# GD32F5xx register map
File version: 1.0
CPU: CM33 r0p1, little endian, MPU, FPU, 4 interrupt priority bits
Registers are 32-bit, read-write, reset 0x0 unless marked. A register's access mark holds for its fields unless they carry their own. Offsets are from the block's base; [hi:lo] are bit positions; {n}, {i} and the like mark numbered series.

## RCU — Reset and clock unit
Base 0x40023800
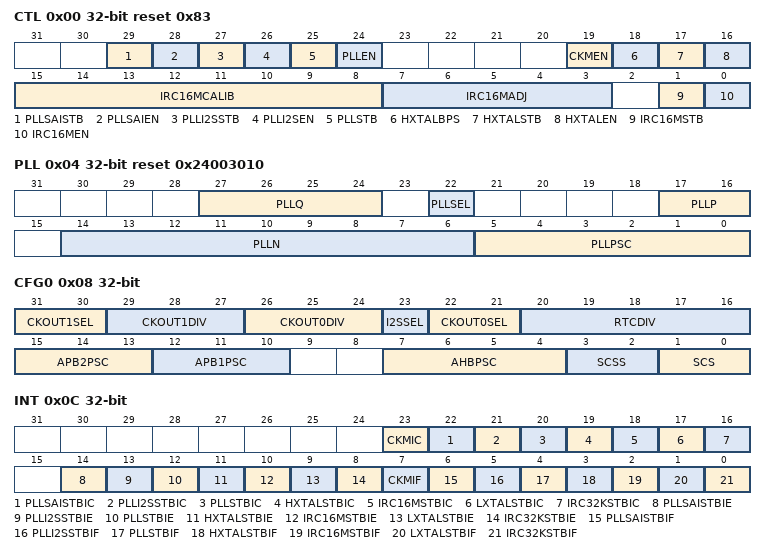
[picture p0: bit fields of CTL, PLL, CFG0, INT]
0x00 CTL access per field reset 0x83 — Control register
  [29] PLLSAISTB ro — PLLSAI clock stabilization flag
  [28] PLLSAIEN rw — PLLSAI enable
  [27] PLLI2SSTB ro — PLLI2S clock stabilization flag
  [26] PLLI2SEN rw — PLLI2S enable
  [25] PLLSTB ro — PLL clock stabilization flag
  [24] PLLEN rw — PLL enable
  [19] CKMEN rw — HXTAL clock monitor enable
  [18] HXTALBPS rw — High speed crystal oscillator (HXTAL) clock bypass mode enable
  [17] HXTALSTB ro — High speed crystal oscillator (HXTAL) clock stabilization flag
  [16] HXTALEN rw — High Speed crystal oscillator (HXTAL) enable
  [15:8] IRC16MCALIB ro — Internal 16MHz RC Oscillator calibration value register
  [7:3] IRC16MADJ rw — Internal 16MHz RC Oscillator clock trim adjust value
  [1] IRC16MSTB ro — IRC16M Internal 16MHz RC Oscillator stabilization flag
  [0] IRC16MEN rw — Internal 16MHz RC oscillator enable
0x04 PLL reset 0x24003010
  [27:24] PLLQ — The PLL Q output frequency division factor from PLL VCO clock
  [22] PLLSEL — PLL clock source selection
  [17:16] PLLP — The PLLP output frequency division factor from PLL VCO clock
  [14:6] PLLN — The PLL VCO clock multiplication factor
  [5:0] PLLPSC — The PLL VCO source clock prescaler
0x08 CFG0 access per field — Clock configuration register 0
  [31:30] CKOUT1SEL rw — CKOUT1 clock source selection
  [29:27] CKOUT1DIV rw — The CK_OUT1 divider which the CK_OUT1 frequency can be reduced
  [26:24] CKOUT0DIV rw — The CK_OUT0 divider which the CK_OUT0 frequency can be reduced
  [23] I2SSEL rw — I2S clock source selection
  [22:21] CKOUT0SEL rw — CKOUT0 clock source selection
  [20:16] RTCDIV rw — RTC clock divider factor
  [15:13] APB2PSC rw — APB2 prescaler selection
  [12:10] APB1PSC rw — APB1 prescaler selection
  [7:4] AHBPSC rw — AHB prescaler selection
  [3:2] SCSS ro — System clock switch status
  [1:0] SCS rw — System clock switch
0x0C INT access per field — Clock interrupt register
  [23] CKMIC wo — HXTAL clock stuck interrupt clear
  [22] PLLSAISTBIC wo — PLLSAI stabilization interrupt clear
  [21] PLLI2SSTBIC wo — PLLI2S stabilization interrupt clear
  [20] PLLSTBIC wo — PLL stabilization interrupt clear
  [19] HXTALSTBIC wo — HXTAL stabilization interrupt clear
  [18] IRC16MSTBIC wo — IRC16M stabilization interrupt clear
  [17] LXTALSTBIC wo — LXTAL stabilization interrupt clear
  [16] IRC32KSTBIC wo — IRC32K stabilization interrupt clear
  [14] PLLSAISTBIE rw — PLLSAI stabilization interrupt enable
  [13] PLLI2SSTBIE rw — PLLI2S stabilization interrupt enable
  [12] PLLSTBIE rw — PLL stabilization interrupt enable
  [11] HXTALSTBIE rw — HXTAL stabilization interrupt enable
  [10] IRC16MSTBIE rw — IRC16M stabilization interrupt enable
  [9] LXTALSTBIE rw — LXTAL stabilization interrupt enable
  [8] IRC32KSTBIE rw — IRC32K stabilization interrupt enable
  [7] CKMIF ro — HXTAL clock stuck interrupt flag
  [6] PLLSAISTBIF ro — PLLSAI stabilization interrupt flag
  [5] PLLI2SSTBIF ro — PLLI2S stabilization interrupt flag
  [4] PLLSTBIF ro — PLL stabilization interrupt flag
  [3] HXTALSTBIF ro — HXTAL stabilization interrupt flag
  [2] IRC16MSTBIF ro — IRC16M stabilization interrupt flag
  [1] LXTALSTBIF ro — LXTAL stabilization interrupt flag
  [0] IRC32KSTBIF ro — IRC32K stabilization interrupt flag
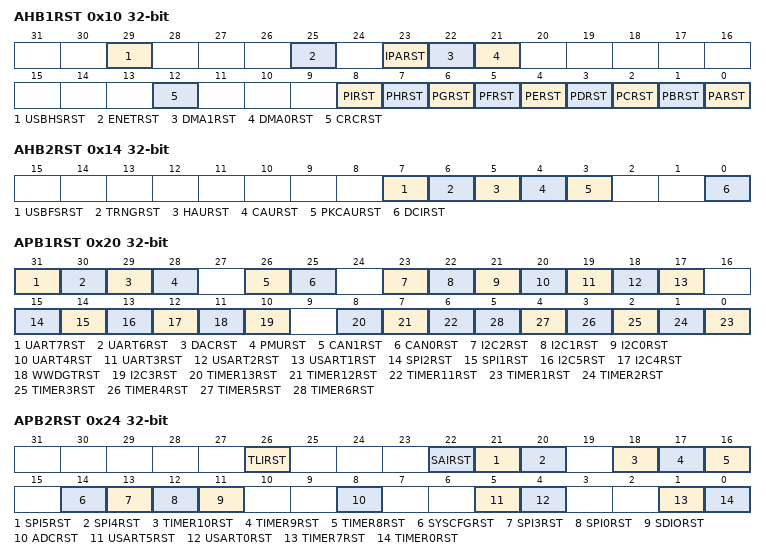
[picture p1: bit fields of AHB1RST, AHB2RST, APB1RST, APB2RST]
0x10 AHB1RST — AHB1 reset register
  [29] USBHSRST — USBHS reset
  [25] ENETRST — Ethernet reset
  [23] IPARST — IPA reset
  [22] DMA1RST — DMA1 reset
  [21] DMA0RST — DMA0 reset
  [12] CRCRST — CRC reset
  [8] PIRST — GPIO port I reset
  [7] PHRST — GPIO port H reset
  [6] PGRST — GPIO port G reset
  [5] PFRST — GPIO port F reset
  [4] PERST — GPIO port E reset
  [3] PDRST — GPIO port D reset
  [2] PCRST — GPIO port C reset
  [1] PBRST — GPIO port B reset
  [0] PARST — GPIO port A reset
0x14 AHB2RST — AHB2 reset register
  [7] USBFSRST — USBFS reset
  [6] TRNGRST — TRNG reset
  [5] HAURST — HAU reset
  [4] CAURST — CAU reset
  [3] PKCAURST — PKCAU reset
  [0] DCIRST — DCI reset
0x18 AHB3RST — AHB3 reset register
  [0] EXMCRST — EXMC reset
0x20 APB1RST — APB1 reset register
  [31] UART7RST — UART7 reset
  [30] UART6RST — UART6 reset
  [29] DACRST — DAC reset
  [28] PMURST — PMU reset
  [26] CAN1RST — CAN1 reset
  [25] CAN0RST — CAN0 reset
  [23] I2C2RST — I2C2 reset
  [22] I2C1RST — I2C1 reset
  [21] I2C0RST — I2C0 reset
  [20] UART4RST — UART4 reset
  [19] UART3RST — UART3 reset
  [18] USART2RST — USART2 reset
  [17] USART1RST — USART1 reset
  [15] SPI2RST — SPI2 reset
  [14] SPI1RST — SPI1 reset
  [13] I2C5RST — I2C5 reset
  [12] I2C4RST — I2C4 reset
  [11] WWDGTRST — WWDGT reset
  [10] I2C3RST — I2C3 reset
  [8] TIMER13RST — TIMER13 reset
  [7] TIMER12RST — TIMER12 reset
  [6] TIMER11RST — TIMER11 reset
  [n-1] TIMER{n}RST (n=1..6) — TIMER{n} reset
0x24 APB2RST — APB2 reset register
  [26] TLIRST — TLI reset
  [22] SAIRST — SAI reset
  [21] SPI5RST — SPI5 reset
  [20] SPI4RST — SPI4 reset
  [18] TIMER10RST — TIMER10 reset
  [17] TIMER9RST — TIMER9 reset
  [16] TIMER8RST — TIMER8 reset
  [14] SYSCFGRST — SYSCFG reset
  [13] SPI3RST — SPI3 reset
  [12] SPI0RST — SPI0 reset
  [11] SDIORST — SDIO reset
  [8] ADCRST — ADC reset
  [5] USART5RST — USART5 reset
  [4] USART0RST — USART0 reset
  [1] TIMER7RST — TIMER7 reset
  [0] TIMER0RST — TIMER0 reset
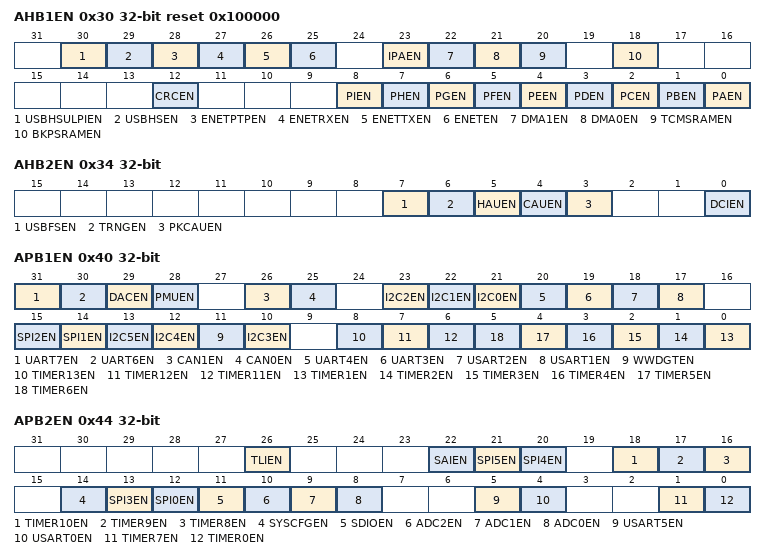
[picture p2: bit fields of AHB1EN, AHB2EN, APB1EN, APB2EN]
0x30 AHB1EN reset 0x100000 — AHB1 enable register
  [30] USBHSULPIEN — USBHS ULPI clock enable
  [29] USBHSEN — USBHS clock enable
  [28] ENETPTPEN — Ethernet PTP clock enable
  [27] ENETRXEN — Ethernet RX clock enable
  [26] ENETTXEN — Ethernet TX clock enable
  [25] ENETEN — Ethernet clock enable
  [23] IPAEN — IPA clock enable
  [22] DMA1EN — DMA1 clock enable
  [21] DMA0EN — DMA0 clock enable
  [20] TCMSRAMEN — TCMSRAM clock enable
  [18] BKPSRAMEN — BKPSRAM clock enable
  [12] CRCEN — CRC clock enable
  [8] PIEN — GPIO port I clock enable
  [7] PHEN — GPIO port H clock enable
  [6] PGEN — GPIO port G clock enable
  [5] PFEN — GPIO port F clock enable
  [4] PEEN — GPIO port E clock enable
  [3] PDEN — GPIO port D clock enable
  [2] PCEN — GPIO port C clock enable
  [1] PBEN — GPIO port B clock enable
  [0] PAEN — GPIO port A clock enable
0x34 AHB2EN — AHB2 enable register
  [7] USBFSEN — USBFS clock enable
  [6] TRNGEN — TRNG clock enable
  [5] HAUEN — HAU clock enable
  [4] CAUEN — CAU clock enable
  [3] PKCAUEN — PKCAU clock enable
  [0] DCIEN — DCI clock enable
0x38 AHB3EN — AHB3 enable register
  [0] EXMCEN — EXMC clock enable
0x40 APB1EN — APB1 enable register
  [31] UART7EN — UART7 clock enable
  [30] UART6EN — UART6 clock enable
  [29] DACEN — DAC clock enable
  [28] PMUEN — PMU clock enable
  [26] CAN1EN — CAN1 clock enable
  [25] CAN0EN — CAN0 clock enable
  [23] I2C2EN — I2C2 clock enable
  [22] I2C1EN — I2C1 clock enable
  [21] I2C0EN — I2C0 clock enable
  [20] UART4EN — UART4 clock enable
  [19] UART3EN — UART3 clock enable
  [18] USART2EN — USART2 clock enable
  [17] USART1EN — USART1 clock enable
  [15] SPI2EN — SPI2 clock enable
  [14] SPI1EN — SPI1 clock enable
  [13] I2C5EN — I2C5 clock enable
  [12] I2C4EN — I2C4 clock enable
  [11] WWDGTEN — WWDGT clock enable
  [10] I2C3EN — I2C3 clock enable
  [8] TIMER13EN — TIMER13 clock enable
  [7] TIMER12EN — TIMER12 clock enable
  [6] TIMER11EN — TIMER11 clock enable
  [n-1] TIMER{n}EN (n=1..6) — TIMER{n} clock enable
0x44 APB2EN — APB2 enable register
  [26] TLIEN — TLI clock enable
  [22] SAIEN — SAI clock enable
  [21] SPI5EN — SPI5 clock enable
  [20] SPI4EN — SPI4 clock enable
  [18] TIMER10EN — TIMER10 clock enable
  [17] TIMER9EN — TIMER9 clock enable
  [16] TIMER8EN — TIMER8 clock enable
  [14] SYSCFGEN — SYSCFG clock enable
  [13] SPI3EN — SPI3 clock enable
  [12] SPI0EN — SPI0 clock enable
  [11] SDIOEN — SDIO clock enable
  [10] ADC2EN — ADC2 clock enable
  [9] ADC1EN — ADC1 clock enable
  [8] ADC0EN — ADC0 clock enable
  [5] USART5EN — USART5 clock enable
  [4] USART0EN — USART0 clock enable
  [1] TIMER7EN — TIMER7 clock enable
  [0] TIMER0EN — TIMER0 clock enable
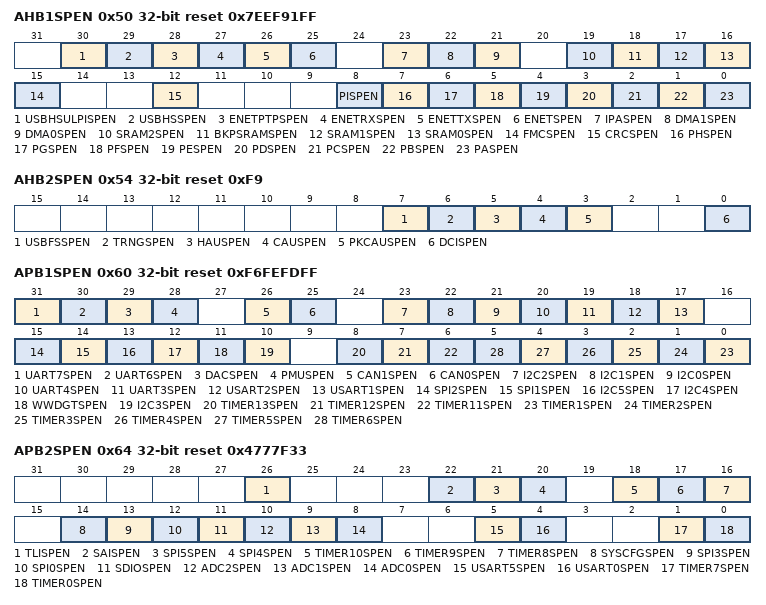
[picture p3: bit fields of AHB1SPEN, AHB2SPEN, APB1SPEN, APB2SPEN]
0x50 AHB1SPEN reset 0x7EEF91FF — AHB1 sleep mode enable register
  [30] USBHSULPISPEN — USBHS ULPI clock enable when sleep mode
  [29] USBHSSPEN — USBHS clock enable when sleep mode
  [28] ENETPTPSPEN — Ethernet PTP clock enable when sleep mode
  [27] ENETRXSPEN — Ethernet RX clock enable when sleep mode
  [26] ENETTXSPEN — Ethernet TX clock enable when sleep mode
  [25] ENETSPEN — Ethernet clock enable when sleep mode
  [23] IPASPEN — IPA clock enable when sleep mode
  [22] DMA1SPEN — DMA1 clock enable when sleep mode
  [21] DMA0SPEN — DMA0 clock enable when sleep mode
  [19] SRAM2SPEN — SRAM2 clock enable when sleep mode
  [18] BKPSRAMSPEN — BKPSRAM clock enable when sleep mode
  [17] SRAM1SPEN — SRAM1 clock enable when sleep mode
  [16] SRAM0SPEN — SRAM0 clock enable when sleep mode
  [15] FMCSPEN — FMC clock enable when sleep mode
  [12] CRCSPEN — CRC clock enable when sleep mode
  [8] PISPEN — GPIO port I clock enable when sleep mode
  [7] PHSPEN — GPIO port H clock enable when sleep mode
  [6] PGSPEN — GPIO port G clock enable when sleep mode
  [5] PFSPEN — GPIO port F clock enable when sleep mode
  [4] PESPEN — GPIO port E clock enable when sleep mode
  [3] PDSPEN — GPIO port D clock enable when sleep mode
  [2] PCSPEN — GPIO port C clock enable when sleep mode
  [1] PBSPEN — GPIO port B clock enable when sleep mode
  [0] PASPEN — GPIO port A clock enable when sleep mode
0x54 AHB2SPEN reset 0xF9 — AHB2 sleep mode enable register
  [7] USBFSSPEN — USBFS clock enable when sleep mode
  [6] TRNGSPEN — TRNG clock enable when sleep mode
  [5] HAUSPEN — HAU clock enable when sleep mode
  [4] CAUSPEN — CAU clock enable when sleep mode
  [3] PKCAUSPEN — PKCAU clock enable when sleep mode
  [0] DCISPEN — DCI clock enable when sleep mode
0x58 AHB3SPEN reset 0x1 — AHB3 sleep mode enable register
  [0] EXMCSPEN — EXMC clock enable when sleep mode
0x60 APB1SPEN reset 0xF6FEFDFF — APB1 sleep mode enable register
  [31] UART7SPEN — UART7 clock enable when sleep mode
  [30] UART6SPEN — UART6 clock enable when sleep mode
  [29] DACSPEN — DAC clock enable when sleep mode
  [28] PMUSPEN — PMU clock enable when sleep mode
  [26] CAN1SPEN — CAN1 clock enable when sleep mode
  [25] CAN0SPEN — CAN0 clock enable when sleep mode
  [23] I2C2SPEN — I2C2 clock enable when sleep mode
  [22] I2C1SPEN — I2C1 clock enable when sleep mode
  [21] I2C0SPEN — I2C0 clock enable when sleep mode
  [20] UART4SPEN — UART4 clock enable when sleep mode
  [19] UART3SPEN — UART3 clock enable when sleep mode
  [18] USART2SPEN — USART2 clock enable when sleep mode
  [17] USART1SPEN — USART1 clock enable when sleep mode
  [15] SPI2SPEN — SPI2 clock enable when sleep mode
  [14] SPI1SPEN — SPI1 clock enable when sleep mode
  [13] I2C5SPEN — I2C5 clock enable when sleep mode
  [12] I2C4SPEN — I2C4 clock enable when sleep mode
  [11] WWDGTSPEN — WWDGT clock enable when sleep mode
  [10] I2C3SPEN — I2C3 clock enable when sleep mode
  [8] TIMER13SPEN — TIMER13 clock enable when sleep mode
  [7] TIMER12SPEN — TIMER12 clock enable when sleep mode
  [6] TIMER11SPEN — TIMER11 clock enable when sleep mode
  [n-1] TIMER{n}SPEN (n=1..6) — TIMER{n} clock enable when sleep mode
0x64 APB2SPEN reset 0x4777F33 — APB2 sleep mode enable register
  [26] TLISPEN — TLI clock enable when sleep mode
  [22] SAISPEN — SAI clock enable when sleep mode
  [21] SPI5SPEN — SPI5 clock enable when sleep mode
  [20] SPI4SPEN — SPI4 clock enable when sleep mode
  [18] TIMER10SPEN — TIMER10 clock enable when sleep mode
  [17] TIMER9SPEN — TIMER9 clock enable when sleep mode
  [16] TIMER8SPEN — TIMER8 clock enable when sleep mode
  [14] SYSCFGSPEN — SYSCFG clock enable when sleep mode
  [13] SPI3SPEN — SPI3 clock enable when sleep mode
  [12] SPI0SPEN — SPI0 clock enable when sleep mode
  [11] SDIOSPEN — SDIO clock enable when sleep mode
  [10] ADC2SPEN — ADC2 clock enable when sleep mode
  [9] ADC1SPEN — ADC1 clock enable when sleep mode
  [8] ADC0SPEN — ADC0 clock enable when sleep mode
  [5] USART5SPEN — USART5 clock enable when sleep mode
  [4] USART0SPEN — USART0 clock enable when sleep mode
  [1] TIMER7SPEN — TIMER7 clock enable when sleep mode
  [0] TIMER0SPEN — TIMER0 clock enable when sleep mode
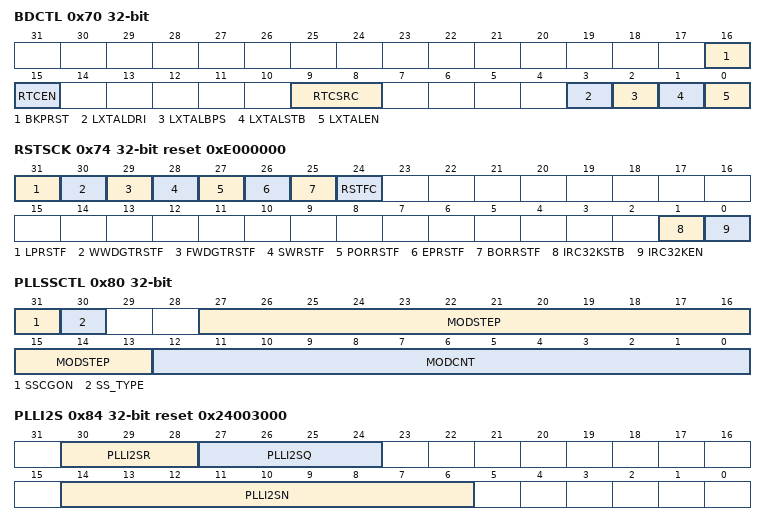
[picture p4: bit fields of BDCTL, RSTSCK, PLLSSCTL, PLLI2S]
0x70 BDCTL access per field — Backup domain control register
  [16] BKPRST rw — Backup domain reset
  [15] RTCEN rw — RTC clock enable
  [9:8] RTCSRC rw — RTC clock entry selection
  [3] LXTALDRI rw — LXTAL drive capability
  [2] LXTALBPS rw — LXTAL bypass mode enable
  [1] LXTALSTB ro — Low speed crystal oscillator stabilization flag
  [0] LXTALEN rw — LXTAL enable
0x74 RSTSCK access per field reset 0xE000000 — Reset source/clock register
  [31] LPRSTF ro — Low-power reset flag
  [30] WWDGTRSTF ro — Window watchdog timer reset flag
  [29] FWDGTRSTF ro — Free watchdog timer reset flag
  [28] SWRSTF ro — Software reset flag
  [27] PORRSTF ro — Power reset flag
  [26] EPRSTF ro — External PIN reset flag
  [25] BORRSTF ro — BOR reset flag
  [24] RSTFC rw — Reset flag clear
  [1] IRC32KSTB ro — IRC32K stabilization flag
  [0] IRC32KEN rw — IRC32K enable
0x80 PLLSSCTL — PLL clock spread spectrum control register
  [31] SSCGON — PLL spread spectrum modulation enable
  [30] SS_TYPE — PLL spread spectrum modulation type select
  [27:13] MODSTEP — These bits configure PLL spread spectrum modulation profile amplitude and frequency.
  [12:0] MODCNT — These bits configure PLL spread spectrum modulation profile amplitude and frequency.
0x84 PLLI2S reset 0x24003000
  [30:28] PLLI2SR — The PLLI2S R output frequency division factor from PLLI2S VCO clock
  [27:24] PLLI2SQ — The PLLI2SQ output frequency division factor from PLLI2S VCO clock
  [14:6] PLLI2SN — The PLLI2S VCO clock multiplication factor
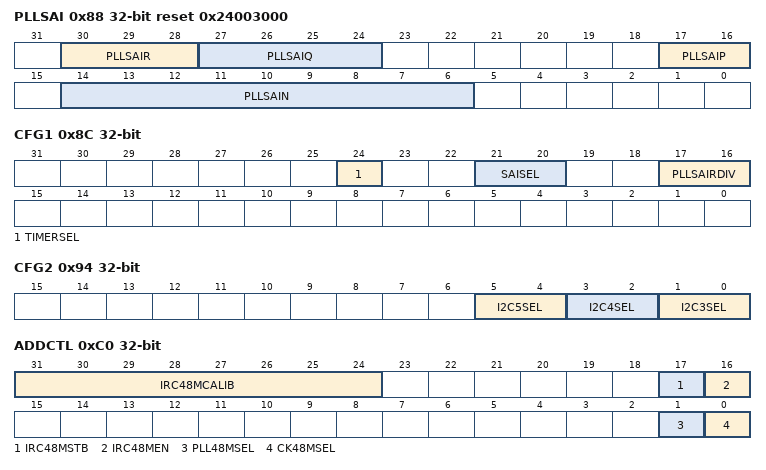
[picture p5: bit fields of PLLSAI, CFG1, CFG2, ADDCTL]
0x88 PLLSAI reset 0x24003000
  [30:28] PLLSAIR — The PLLSAI R output frequency division factor from PLLSAI VCO clock
  [27:24] PLLSAIQ — The PLLSAIQ output frequency division factor from PLLSAI VCO clock
  [17:16] PLLSAIP — The PLLSAI P output frequency division factor from PLLSAI VCO clock
  [14:6] PLLSAIN — The PLLSAI VCO clock multiplication factor
0x8C CFG1 — Clock configuration register 1
  [24] TIMERSEL — TIMER clock selection
  [21:20] SAISEL — SAI clock selection
  [17:16] PLLSAIRDIV — The divider factor from PLLSAIR clock
0x94 CFG2 — Clock configuration register 2
  [5:4] I2C5SEL — I2C5 clock source selection
  [3:2] I2C4SEL — I2C4 clock source selection
  [1:0] I2C3SEL — I2C3 clock source selection
0xC0 ADDCTL access per field — Additional clock control register
  [31:24] IRC48MCALIB ro — Internal 48MHz RC oscillator calibration value register
  [17] IRC48MSTB ro — Internal 48MHz RC oscillator clock stabilization Flag
  [16] IRC48MEN rw — Internal 48MHz RC oscillator enable
  [1] PLL48MSEL rw — PLL48M clock selection
  [0] CK48MSEL rw — 48MHz clock selection
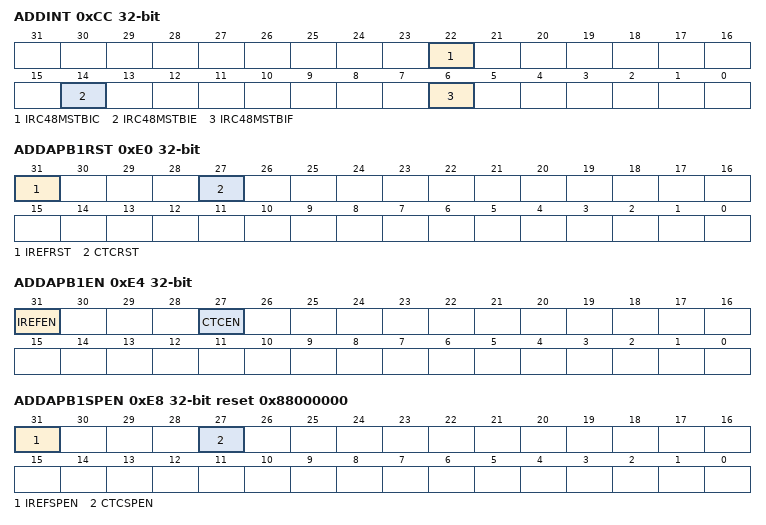
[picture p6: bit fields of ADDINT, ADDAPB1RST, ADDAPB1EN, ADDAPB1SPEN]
0xCC ADDINT access per field — Additional clock interrupt register
  [22] IRC48MSTBIC wo — Internal 48 MHz RC oscillator Stabilization interrupt clear
  [14] IRC48MSTBIE rw — Internal 48 MHz RC oscillator Stabilization interrupt enable
  [6] IRC48MSTBIF ro — IRC48M stabilization interrupt flag
0xE0 ADDAPB1RST — APB1 additional reset register
  [31] IREFRST — IREF reset
  [27] CTCRST — CTC reset
0xE4 ADDAPB1EN — APB1 additional enable register
  [31] IREFEN — IREF interface clock enable
  [27] CTCEN — CTC clock enable
0xE8 ADDAPB1SPEN reset 0x88000000 — APB1 additional sleep mode enable register
  [31] IREFSPEN — IREF interface clock enable when sleep mode
  [27] CTCSPEN — CTC clock enable when sleep mode
0x100 VKEY wo — Voltage key register
  [31:0] KEY — The key of RCU_DSV register
0x134 DSV — Deep-sleep mode voltage register
  [2:0] DSLPVS — Deep-sleep mode voltage select
